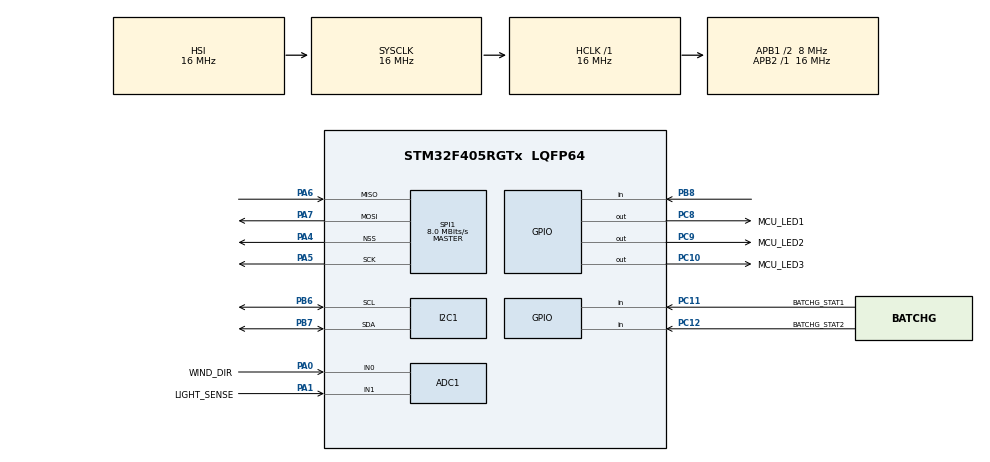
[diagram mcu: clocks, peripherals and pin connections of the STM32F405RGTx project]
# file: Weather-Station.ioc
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ADC1.Channel-0\#ChannelRegularConversion=ADC_CHANNEL_0
ADC1.NbrOfConversionFlag=1
ADC1.Rank-0\#ChannelRegularConversion=1
ADC1.SamplingTime-0\#ChannelRegularConversion=ADC_SAMPLETIME_3CYCLES
ADC1.master=1
FREERTOS.Tasks01=defaultTask,24,128,StartDefaultTask,Default,NULL,Dynamic,NULL,NULL;chargerStatTask,8,128,startChargerStatusTask,As external,NULL,Dynamic,NULL,NULL
Mcu.Family=STM32F4
Mcu.Name=STM32F405RGTx
Mcu.Package=LQFP64
NVIC.PriorityGroup=NVIC_PRIORITYGROUP_4
NVIC.TIM1_UP_TIM10_IRQn=true\:15\:0\:false\:false\:true\:false\:false\:true\:true
NVIC.TimeBase=TIM1_UP_TIM10_IRQn
NVIC.TimeBaseIP=TIM1
PA0-WKUP.GPIO_Label=WIND_DIR
PA0-WKUP.Signal=ADCx_IN0
PA1.GPIO_Label=LIGHT_SENSE
PA1.Signal=ADCx_IN1
PA13.Mode=Trace_Asynchronous_SW
PA13.Signal=SYS_JTMS-SWDIO
PA14.Mode=Trace_Asynchronous_SW
PA14.Signal=SYS_JTCK-SWCLK
PA4.Mode=NSS_Signal_Hard_Output
PA4.Signal=SPI1_NSS
PA5.Mode=Full_Duplex_Master
PA5.Signal=SPI1_SCK
PA6.Mode=Full_Duplex_Master
PA6.Signal=SPI1_MISO
PA7.Mode=Full_Duplex_Master
PA7.Signal=SPI1_MOSI
PB3.Mode=Trace_Asynchronous_SW
PB3.Signal=SYS_JTDO-SWO
PB6.Mode=I2C
PB6.Signal=I2C1_SCL
PB7.Mode=I2C
PB7.Signal=I2C1_SDA
PB8.GPIO_PuPd=GPIO_PULLUP
PB8.Signal=GPIO_Input
PC10.GPIO_Label=MCU_LED3
PC10.Signal=GPIO_Output
PC11.GPIO_Label=BATCHG_STAT1
PC11.Signal=GPIO_Input
PC12.GPIO_Label=BATCHG_STAT2
PC12.Signal=GPIO_Input
PC8.GPIO_Label=MCU_LED1
PC8.Signal=GPIO_Output
PC9.GPIO_Label=MCU_LED2
PC9.Signal=GPIO_Output
ProjectManager.HeapSize=0x200
ProjectManager.StackSize=0x400
ProjectManager.TargetToolchain=STM32CubeIDE
RCC.48MHZClocksFreq_Value=25000000
RCC.AHBFreq_Value=16000000
RCC.APB1CLKDivider=RCC_HCLK_DIV2
RCC.APB1Freq_Value=8000000
RCC.APB1TimFreq_Value=16000000
RCC.APB2Freq_Value=16000000
RCC.APB2TimFreq_Value=16000000
RCC.CortexFreq_Value=16000000
RCC.HCLKFreq_Value=16000000
RCC.HSE_VALUE=25000000
RCC.HSI_VALUE=16000000
RCC.LSE_VALUE=32768
RCC.PLLM=8
RCC.PLLN=50
RCC.SYSCLKFreq_VALUE=16000000
RCC.VCOOutputFreq_Value=100000000
SH.ADCx_IN0.0=ADC1_IN0,IN0
SH.ADCx_IN1.0=ADC1_IN1,IN1
SPI1.BaudRatePrescaler=SPI_BAUDRATEPRESCALER_2
SPI1.CalculateBaudRate=8.0 MBits/s
SPI1.Direction=SPI_DIRECTION_2LINES
SPI1.Mode=SPI_MODE_MASTER
SPI1.VirtualNSS=VM_NSSHARD
SPI1.VirtualType=VM_MASTER
VP_FREERTOS_VS_CMSIS_V2.Mode=CMSIS_V2
VP_SYS_VS_tim1.Mode=TIM1
board=custom

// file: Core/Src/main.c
/* USER CODE BEGIN Header */
/**
  ******************************************************************************
  * @file           : main.c
  * @brief          : Main program body
  ******************************************************************************
  * @attention
  *
  * Copyright (c) 2024 STMicroelectronics.
  * All rights reserved.
  *
  * This software is licensed under terms that can be found in the LICENSE file
  * in the root directory of this software component.
  * If no LICENSE file comes with this software, it is provided AS-IS.
  *
  ******************************************************************************
  */
/* USER CODE END Header */
#include "main.h"
#include "cmsis_os.h"
#include "adc.h"
#include "i2c.h"
#include "spi.h"
#include "gpio.h"

/* USER CODE BEGIN Includes */
#include "led_manager.h"
/* USER CODE END Includes */

void SystemClock_Config(void);
void MX_FREERTOS_Init(void);

int main(void)
{

  /* MCU Configuration--------------------------------------------------------*/

  /* Reset of all peripherals, Initializes the Flash interface and the Systick. */
  HAL_Init();

  /* USER CODE BEGIN Init */
  LED_Manager_Init();
  /* USER CODE END Init */

  /* Configure the system clock */
  SystemClock_Config();

  /* Initialize all configured peripherals */
  MX_GPIO_Init();
  MX_ADC1_Init();
  MX_I2C1_Init();
  MX_SPI1_Init();

  /* Init scheduler */
  osKernelInitialize();

  /* Call init function for freertos objects (in cmsis_os2.c) */
  MX_FREERTOS_Init();

  /* Start scheduler */
  osKernelStart();

  /* We should never get here as control is now taken by the scheduler */

}

void SystemClock_Config(void)
{
  RCC_OscInitTypeDef RCC_OscInitStruct = {0};
  RCC_ClkInitTypeDef RCC_ClkInitStruct = {0};

  /** Configure the main internal regulator output voltage
  */
  __HAL_RCC_PWR_CLK_ENABLE();
  __HAL_PWR_VOLTAGESCALING_CONFIG(PWR_REGULATOR_VOLTAGE_SCALE1);

  /** Initializes the RCC Oscillators according to the specified parameters
  * in the RCC_OscInitTypeDef structure.
  */
  RCC_OscInitStruct.OscillatorType = RCC_OSCILLATORTYPE_HSI;
  RCC_OscInitStruct.HSIState = RCC_HSI_ON;
  RCC_OscInitStruct.HSICalibrationValue = RCC_HSICALIBRATION_DEFAULT;
  RCC_OscInitStruct.PLL.PLLState = RCC_PLL_NONE;
  if (HAL_RCC_OscConfig(&RCC_OscInitStruct) != HAL_OK)
  {
    Error_Handler();
  }

  /** Initializes the CPU, AHB and APB buses clocks
  */
  RCC_ClkInitStruct.ClockType = RCC_CLOCKTYPE_HCLK|RCC_CLOCKTYPE_SYSCLK
                              |RCC_CLOCKTYPE_PCLK1|RCC_CLOCKTYPE_PCLK2;
  RCC_ClkInitStruct.SYSCLKSource = RCC_SYSCLKSOURCE_HSI;
  RCC_ClkInitStruct.AHBCLKDivider = RCC_SYSCLK_DIV1;
  RCC_ClkInitStruct.APB1CLKDivider = RCC_HCLK_DIV2;
  RCC_ClkInitStruct.APB2CLKDivider = RCC_HCLK_DIV1;

  if (HAL_RCC_ClockConfig(&RCC_ClkInitStruct, FLASH_LATENCY_0) != HAL_OK)
  {
    Error_Handler();
  }
}

void HAL_TIM_PeriodElapsedCallback(TIM_HandleTypeDef *htim)
{
  if (htim->Instance == TIM1) {
    HAL_IncTick();
  }
}

void Error_Handler(void)
{
  __disable_irq();
  while (1)
  {
  }
}

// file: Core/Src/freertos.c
/* USER CODE BEGIN Header */
/**
  ******************************************************************************
  * File Name          : freertos.c
  * Description        : Code for freertos applications
  ******************************************************************************
  * @attention
  *
  * Copyright (c) 2024 STMicroelectronics.
  * All rights reserved.
  *
  * This software is licensed under terms that can be found in the LICENSE file
  * in the root directory of this software component.
  * If no LICENSE file comes with this software, it is provided AS-IS.
  *
  ******************************************************************************
  */
/* USER CODE END Header */

#include "FreeRTOS.h"
#include "task.h"
#include "main.h"
#include "cmsis_os.h"

/* USER CODE BEGIN Includes */
#include "charger.h"
#include "temp.h"
/* USER CODE END Includes */

/* USER CODE BEGIN Variables */
/* Definitions for chargerStatTask */
osThreadId_t readTempTaskHandle;
const osThreadAttr_t readTempTask_attributes = {
  .name = "readTempTask",
  .stack_size = 128 * 4,
  .priority = (osPriority_t) osPriorityLow,
};

/* USER CODE END Variables */
/* Definitions for defaultTask */
osThreadId_t defaultTaskHandle;
const osThreadAttr_t defaultTask_attributes = {
  .name = "defaultTask",
  .stack_size = 128 * 4,
  .priority = (osPriority_t) osPriorityNormal,
};
/* Definitions for chargerStatTask */
osThreadId_t chargerStatTaskHandle;
const osThreadAttr_t chargerStatTask_attributes = {
  .name = "chargerStatTask",
  .stack_size = 128 * 4,
  .priority = (osPriority_t) osPriorityLow,
};

void StartDefaultTask(void *argument);
extern void startChargerStatusTask(void *argument);
extern void startReadTempTask(void *argument);

void MX_FREERTOS_Init(void); /* (MISRA C 2004 rule 8.1) */

void MX_FREERTOS_Init(void) {

  /* Create the thread(s) */
  /* creation of defaultTask */
  defaultTaskHandle = osThreadNew(StartDefaultTask, NULL, &defaultTask_attributes);

  /* creation of chargerStatTask */
  chargerStatTaskHandle = osThreadNew(startChargerStatusTask, NULL, &chargerStatTask_attributes);

  chargerStatTaskHandle = osThreadNew(startReadTempTask, NULL, &readTempTask_attributes);

}

void StartDefaultTask(void *argument)
{
  for(;;)
  {
    osDelay(1);
  }
}
